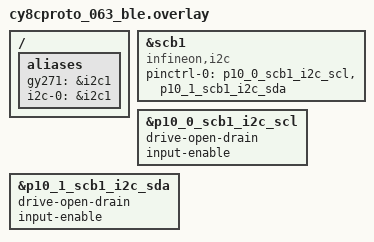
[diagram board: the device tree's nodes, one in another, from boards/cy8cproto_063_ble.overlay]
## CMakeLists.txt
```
# SPDX-License-Identifier: Apache-2.0

cmake_minimum_required(VERSION 3.15.7)
find_package(Zephyr REQUIRED HINTS $ENV{ZEPHYR_BASE})
project(i2c_api)

FILE(GLOB app_sources src/*.c)
target_sources(app PRIVATE ${app_sources})
```

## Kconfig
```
# Copyright (c) 2024 Renesas Electronics Corporation
# SPDX-License-Identifier: Apache-2.0

mainmenu "I2C API Test"

source "Kconfig.zephyr"

choice
	prompt "Select GY271 Sensor Type"
	default SENSOR_GY271_HMC

config SENSOR_GY271_HMC
	bool "Use gy271 HMC type sensor"
	help
	  Use to enable the use of gy271 HMC sensor

config SENSOR_GY271_QMC
	bool "Use gy271 QMC type sensor"
	help
	  Use to enable the use of gy271 QMC sensor

endchoice
```

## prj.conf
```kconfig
CONFIG_I2C=y
CONFIG_ZTEST=y

CONFIG_SYS_TIMEOUT_LEGACY_API=n
```

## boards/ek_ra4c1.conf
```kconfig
# Copyright (c) 2025 Renesas Electronics Corporation
# SPDX-License-Identifier: Apache-2.0

CONFIG_SENSOR_GY271_HMC=y
```

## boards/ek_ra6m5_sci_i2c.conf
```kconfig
CONFIG_I2C=y
CONFIG_ZTEST=y
CONFIG_SENSOR_GY271_QMC=y
```

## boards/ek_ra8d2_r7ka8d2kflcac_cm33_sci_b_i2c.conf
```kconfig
# Copyright (c) 2026 Renesas Electronics Corporation
# SPDX-License-Identifier: Apache-2.0

CONFIG_SENSOR_GY271_QMC=y
```

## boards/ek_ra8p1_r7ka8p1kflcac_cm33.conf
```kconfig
# Copyright (c) 2025 Renesas Electronics Corporation
# SPDX-License-Identifier: Apache-2.0

CONFIG_SENSOR_GY271_QMC=y
```

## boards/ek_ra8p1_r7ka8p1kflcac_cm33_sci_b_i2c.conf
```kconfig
# Copyright (c) 2025 Renesas Electronics Corporation
# SPDX-License-Identifier: Apache-2.0

CONFIG_I2C=y
CONFIG_ZTEST=y
CONFIG_SENSOR_GY271_QMC=y
```

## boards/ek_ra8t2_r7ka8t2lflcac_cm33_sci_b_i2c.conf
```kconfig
# Copyright (c) 2026 Renesas Electronics Corporation
# SPDX-License-Identifier: Apache-2.0

CONFIG_SENSOR_GY271_HMC=y
```

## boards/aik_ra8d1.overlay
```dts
/*
 * Copyright (c) 2026 Renesas Electronics Corporation
 *
 * SPDX-License-Identifier: Apache-2.0
 */

/ {
	aliases {
		i2c-0 = &pmod1_i2c;
		gy271 = &pmod1_i2c;
	};
};

&pmod1_i2c {
	status = "okay";
};
```

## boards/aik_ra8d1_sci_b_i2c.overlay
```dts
/*
 * Copyright (c) 2026 Renesas Electronics Corporation
 *
 * SPDX-License-Identifier: Apache-2.0
 */

/ {
	aliases {
		i2c-0 = &pmod6_i2c;
		gy271 = &pmod6_i2c;
	};
};

&pmod6_i2c {
	status = "okay";
};
```

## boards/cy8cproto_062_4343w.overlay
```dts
/*
 * Copyright (c) 2023 Cypress Semiconductor Corporation (an Infineon company) or
 * an affiliate of Cypress Semiconductor Corporation
 *
 * SPDX-License-Identifier: Apache-2.0
 */

/ {
	aliases {
		gy271 = &i2c3;
	};
};

&i2c3 {
	status = "okay";
};
```

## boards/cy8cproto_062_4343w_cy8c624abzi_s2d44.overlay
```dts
/*
 * Copyright (c) 2021 Cypress Semiconductor Corporation.
 * SPDX-License-Identifier: Apache-2.0
 */

/ {
	aliases {
		gy271 = &i2c3;
	};
};

&i2c3 {
	status = "okay";
};
```

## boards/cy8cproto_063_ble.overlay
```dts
/*
 * SPDX-License-Identifier: Apache-2.0
 *
 * Copyright (c) 2023 Cypress Semiconductor Corporation (an Infineon company) or
 * an affiliate of Cypress Semiconductor Corporation
 */

/ {
	aliases {
		gy271 = &i2c1;
		i2c-0 = &i2c1;
	};
};

i2c1: &scb1 {
	compatible = "infineon,i2c";
	pinctrl-0 = <&p10_0_scb1_i2c_scl &p10_1_scb1_i2c_sda>;
	pinctrl-names = "default";

	status = "okay";
};

/* Configure pin control bias mode for i2c pins */
&p10_0_scb1_i2c_scl {
	drive-open-drain;
	input-enable;
};

&p10_1_scb1_i2c_sda {
	drive-open-drain;
	input-enable;
};
```

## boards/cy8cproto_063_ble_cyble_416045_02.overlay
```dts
/*
 * SPDX-License-Identifier: Apache-2.0
 *
 * Copyright (c) 2023 Cypress Semiconductor Corporation (an Infineon company) or
 * an affiliate of Cypress Semiconductor Corporation
 */

/ {
	aliases {
		gy271 = &i2c1;
		i2c-0 =&i2c1;
	};
};

i2c1: &scb1 {
	compatible = "infineon,cat1-i2c";

	status = "okay";
	pinctrl-0 = <&p10_0_scb1_i2c_scl &p10_1_scb1_i2c_sda>;
	pinctrl-names = "default";
};

/* Configure pin control bias mode for i2c pins */
&p10_0_scb1_i2c_scl {
	drive-open-drain;
	input-enable;
};

&p10_1_scb1_i2c_sda {
	drive-open-drain;
	input-enable;
};
```

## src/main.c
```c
/*
 * Copyright (c) 2016 Intel Corporation
 *
 * SPDX-License-Identifier: Apache-2.0
 */

#include <zephyr/kernel.h>
#include <zephyr/ztest.h>

extern void test_i2c_gy271(void);
extern void test_i2c_burst_gy271(void);

void test_main(void)
{
	ztest_test_suite(i2c_test,
			 ztest_unit_test(test_i2c_gy271),
			 ztest_unit_test(test_i2c_burst_gy271));
	ztest_run_test_suite(i2c_test);
}
```

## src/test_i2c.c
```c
/*
 * Copyright (c) 2016 Intel Corporation
 *
 * SPDX-License-Identifier: Apache-2.0
 */

/*
 * @addtogroup t_i2c_basic
 * @{
 * @defgroup t_i2c_read_write test_i2c_read_write
 * @brief TestPurpose: verify I2C master can read and write
 * @}
 */

#include <zephyr/drivers/i2c.h>
#include <zephyr/kernel.h>
#include <zephyr/ztest.h>

#if DT_NODE_HAS_STATUS_OKAY(DT_ALIAS(i2c_0))
#define I2C_DEV_NODE DT_ALIAS(i2c_0)
#elif DT_NODE_HAS_STATUS_OKAY(DT_ALIAS(i2c_1))
#define I2C_DEV_NODE DT_ALIAS(i2c_1)
#elif DT_NODE_HAS_STATUS_OKAY(DT_ALIAS(i2c_2))
#define I2C_DEV_NODE DT_ALIAS(i2c_2)
#else
#error "Please set the correct I2C device"
#endif

uint32_t i2c_cfg = I2C_SPEED_SET(I2C_SPEED_STANDARD) | I2C_MODE_CONTROLLER;

#define GY271_HMC_ADDR (0x1E)
#define GY271_QMC_ADDR (0x0D)

#if defined(CONFIG_SENSOR_GY271_QMC)
#define GY271_ADDR GY271_QMC_ADDR
#elif defined(CONFIG_SENSOR_GY271_HMC)
#define GY271_ADDR GY271_HMC_ADDR
#else
#error "No sensor type defined"
#endif

static int test_gy271(void)
{
	unsigned char datas[6];
	const struct device *const i2c_dev = DEVICE_DT_GET(I2C_DEV_NODE);
	uint32_t i2c_cfg_tmp;

	if (!device_is_ready(i2c_dev)) {
		TC_PRINT("I2C device is not ready\n");
		return TC_FAIL;
	}

	/* 1. Verify i2c_configure() */
	if (i2c_configure(i2c_dev, i2c_cfg)) {
		TC_PRINT("I2C config failed\n");
		return TC_FAIL;
	}

	/* 2. Verify i2c_get_config() */
	if (i2c_get_config(i2c_dev, &i2c_cfg_tmp)) {
		TC_PRINT("I2C get_config failed\n");
		return TC_FAIL;
	}
	if (i2c_cfg != i2c_cfg_tmp) {
		TC_PRINT("I2C get_config returned invalid config\n");
		return TC_FAIL;
	}

#ifdef CONFIG_SENSOR_GY271_QMC
	datas[0] = 0x09;
	datas[1] = 0x01;

	if (i2c_write(i2c_dev, datas, 2, GY271_ADDR)) {
		TC_PRINT("Fail to configure sensor GY271\n");
		return TC_FAIL;
	}
#else /* GY271 HMC */
	datas[0] = 0x01;
	datas[1] = 0x20;

	/* 3. verify i2c_write() */
	if (i2c_write(i2c_dev, datas, 2, GY271_ADDR)) {
		TC_PRINT("Fail to configure sensor GY271\n");
		return TC_FAIL;
	}

	datas[0] = 0x02;
	datas[1] = 0x00;
	if (i2c_write(i2c_dev, datas, 2, GY271_ADDR)) {
		TC_PRINT("Fail to configure sensor GY271\n");
		return TC_FAIL;
	}
#endif

	k_sleep(K_MSEC(1));

#ifdef CONFIG_SENSOR_GY271_QMC
	/* Sensor data bits start from 0x00 to 0x05 */
	datas[0] = 0x00;
#else /* GY271 HMC */
	datas[0] = 0x03;
#endif

	if (i2c_write(i2c_dev, datas, 1, GY271_ADDR)) {
		TC_PRINT("Fail to write to sensor GY271\n");
		return TC_FAIL;
	}

	(void)memset(datas, 0, sizeof(datas));

	/* 4. verify i2c_read() */
	if (i2c_read(i2c_dev, datas, 6, GY271_ADDR)) {
		TC_PRINT("Fail to fetch sample from sensor GY271\n");
		return TC_FAIL;
	}

	TC_PRINT("axis raw data: %d %d %d %d %d %d\n", datas[0], datas[1], datas[2], datas[3],
		 datas[4], datas[5]);

	return TC_PASS;
}

static int test_burst_gy271(void)
{
	unsigned char datas[6];
	const struct device *const i2c_dev = DEVICE_DT_GET(I2C_DEV_NODE);
	uint32_t i2c_cfg_tmp;

	if (!device_is_ready(i2c_dev)) {
		TC_PRINT("I2C device is not ready\n");
		return TC_FAIL;
	}

	/* 1. verify i2c_configure() */
	if (i2c_configure(i2c_dev, i2c_cfg)) {
		TC_PRINT("I2C config failed\n");
		return TC_FAIL;
	}

	/* 2. Verify i2c_get_config() */
	if (i2c_get_config(i2c_dev, &i2c_cfg_tmp)) {
		TC_PRINT("I2C get_config failed\n");
		return TC_FAIL;
	}
	if (i2c_cfg != i2c_cfg_tmp) {
		TC_PRINT("I2C get_config returned invalid config\n");
		return TC_FAIL;
	}

#ifdef CONFIG_SENSOR_GY271_QMC
	datas[0] = 0x09;
	datas[1] = 0x01;

	if (i2c_burst_write(i2c_dev, GY271_ADDR, 0x00, datas, 2)) {
		TC_PRINT("Fail to configure sensor GY271 QMC\n");
	}
#else
	datas[0] = 0x01;
	datas[1] = 0x20;
	datas[2] = 0x02;
	datas[3] = 0x00;

	/* 3. verify i2c_burst_write() */
	if (i2c_burst_write(i2c_dev, GY271_ADDR, 0x00, datas, 4)) {
		TC_PRINT("Fail to write to sensor GY271\n");
		return TC_FAIL;
	}

	k_sleep(K_MSEC(1));

	(void)memset(datas, 0, sizeof(datas));
#endif

#ifdef CONFIG_SENSOR_GY271_QMC
	/* Sensor data bits start from 0x00 to 0x05 */
	int start_bit = 0x00;
#else /* GY271 HMC */
	int start_bit = 0x03;
#endif
	/* 4. verify i2c_burst_read() */
	if (i2c_burst_read(i2c_dev, GY271_ADDR, start_bit, datas, 6)) {
		TC_PRINT("Fail to fetch sample from sensor GY271\n");
		return TC_FAIL;
	}

	TC_PRINT("axis raw data: %d %d %d %d %d %d\n", datas[0], datas[1], datas[2], datas[3],
		 datas[4], datas[5]);

	return TC_PASS;
}

ZTEST(i2c_gy271, test_i2c_gy271)
{
	zassert_true(test_gy271() == TC_PASS);
}

ZTEST(i2c_gy271, test_i2c_burst_gy271)
{
	zassert_true(test_burst_gy271() == TC_PASS);
}

ZTEST_SUITE(i2c_gy271, NULL, NULL, NULL, NULL, NULL);
```
